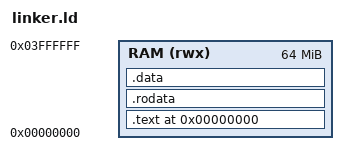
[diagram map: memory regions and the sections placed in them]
ENTRY(_start)

MEMORY
{
    RAM (rwx) : ORIGIN = 0x00000000, LENGTH = 64M
}

SECTIONS
{
    . = 0x00000000;

    .text : {
        *(.text._start)
        *(.text*)
    } > RAM

    .rodata : {
        *(.rodata*)
    } > RAM

    .data : {
        *(.data*)
    } > RAM

    _end = .;
    _stack = 0x02800000;
}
